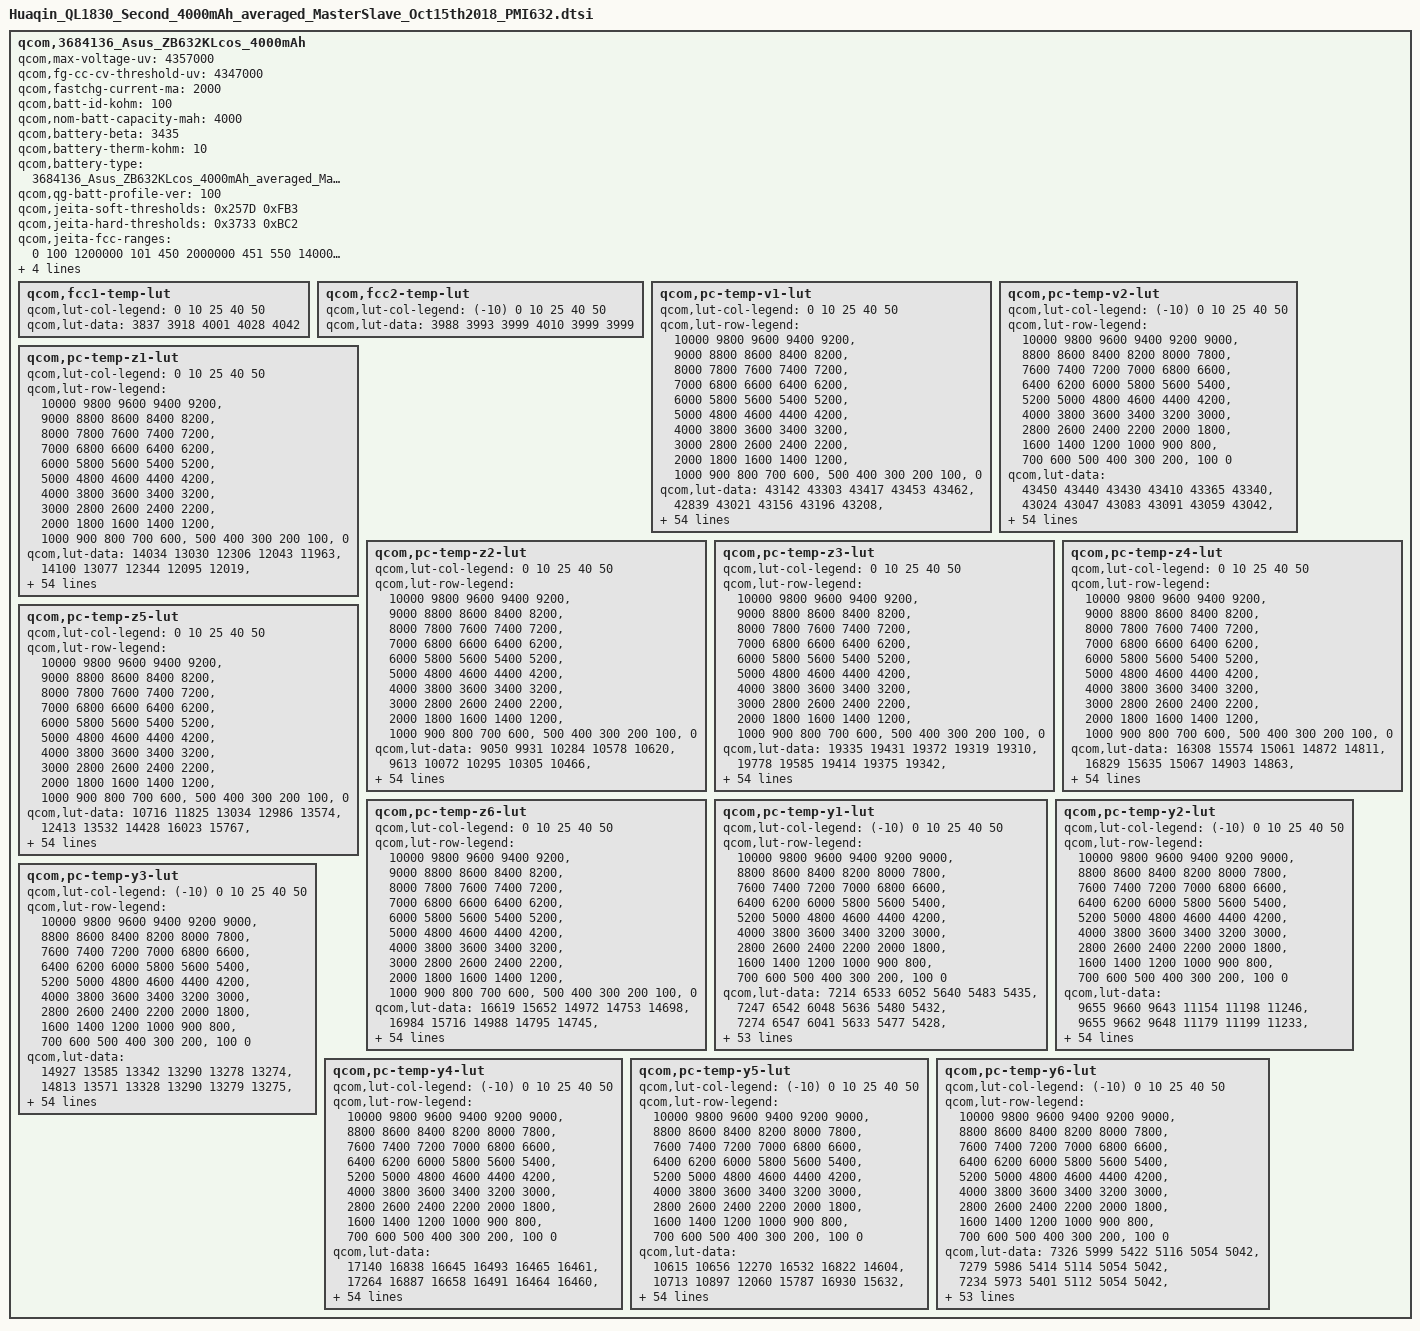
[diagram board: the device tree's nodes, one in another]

qcom,3684136_Asus_ZB632KLcos_4000mAh {
    /* 3684136_Asus_ZB632KLcos_4000mAh_averaged_MasterSlave_Oct15th2018 */
    qcom,max-voltage-uv = <4357000>;
    qcom,fg-cc-cv-threshold-uv = <4347000>;
//huaqin add by wenyaqi for jeita and FCC 2000mA at 20181016 start
    qcom,fastchg-current-ma = <2000>;
//huaqin add by wenyaqi for jeita and FCC 2000mA at 20181016 end
    qcom,batt-id-kohm = <100>;
    qcom,nom-batt-capacity-mah = <4000>;
    qcom,battery-beta = <3435>;
    qcom,battery-therm-kohm = <10>;
    qcom,battery-type = "3684136_Asus_ZB632KLcos_4000mAh_averaged_MasterSlave_Oct15th2018";
    qcom,qg-batt-profile-ver = <100>;
//huaqin add by wenyaqi for jeita and FCC 2000mA at 20181016 start
/* COOL = 15 DegC, WARM = 45 DegC */
    qcom,jeita-soft-thresholds = <0x257D 0xFB3>;
    /* COLD = 0 DegC, HOT = 55 DegC */
    qcom,jeita-hard-thresholds = <0x3733 0xBC2>;
    qcom,jeita-fcc-ranges = <0   100  1200000
                               101  450  2000000
                               451  550  1400000>;
    qcom,jeita-fv-ranges = <0   450  4357000
                            451 550  4100000>;
/*here step charge do not limit current*/
    qcom,step-chg-ranges = <3500000  4200000  2000000
                            4210000  4357000  2000000>;
//huaqin add by wenyaqi for jeita and FCC 2000mA at 20181016 end

	qcom,fcc1-temp-lut {
		qcom,lut-col-legend = <0 10 25 40 50>;
		qcom,lut-data = <3837 3918 4001 4028 4042>;
	};

	qcom,fcc2-temp-lut {
		qcom,lut-col-legend = <(-10) 0 10 25 40 50>;
		qcom,lut-data = <3988 3993 3999 4010 3999 3999>;
	};

	qcom,pc-temp-v1-lut {
		qcom,lut-col-legend = <0 10 25 40 50>;
		qcom,lut-row-legend = <10000 9800 9600 9400 9200>,
			<9000 8800 8600 8400 8200>,
			<8000 7800 7600 7400 7200>,
			<7000 6800 6600 6400 6200>,
			<6000 5800 5600 5400 5200>,
			<5000 4800 4600 4400 4200>,
			<4000 3800 3600 3400 3200>,
			<3000 2800 2600 2400 2200>,
			<2000 1800 1600 1400 1200>,
			<1000 900 800 700 600>,
			<500 400 300 200 100>,
			<0>;
		qcom,lut-data = <43142 43303 43417 43453 43462>,
			<42839 43021 43156 43196 43208>,
			<42573 42757 42884 42933 42950>,
			<42325 42505 42624 42677 42697>,
			<42092 42264 42377 42430 42454>,
			<41872 42033 42137 42189 42217>,
			<41660 41811 41904 41954 41982>,
			<41458 41595 41676 41723 41748>,
			<41259 41385 41453 41496 41519>,
			<41055 41179 41233 41270 41292>,
			<40848 40981 41021 41048 41070>,
			<40627 40789 40822 40837 40855>,
			<40361 40573 40626 40633 40646>,
			<40095 40301 40414 40435 40445>,
			<39903 40045 40181 40238 40249>,
			<39762 39881 39975 40048 40061>,
			<39636 39760 39820 39874 39883>,
			<39510 39637 39686 39709 39715>,
			<39390 39502 39544 39550 39552>,
			<39274 39366 39403 39406 39405>,
			<39161 39232 39242 39253 39253>,
			<39052 39100 39014 39051 39057>,
			<38947 38952 38763 38815 38819>,
			<38845 38747 38601 38634 38631>,
			<38748 38536 38491 38505 38500>,
			<38657 38411 38402 38396 38390>,
			<38571 38329 38324 38300 38292>,
			<38491 38271 38256 38215 38204>,
			<38415 38230 38195 38143 38128>,
			<38347 38199 38138 38079 38059>,
			<38290 38169 38089 38026 37999>,
			<38241 38141 38047 37981 37949>,
			<38203 38115 38011 37943 37905>,
			<38169 38088 37980 37909 37867>,
			<38147 38064 37955 37883 37839>,
			<38142 38038 37928 37853 37808>,
			<38141 38018 37902 37817 37767>,
			<38139 37992 37873 37776 37717>,
			<38104 37943 37827 37721 37656>,
			<38031 37862 37749 37649 37581>,
			<37945 37770 37654 37562 37492>,
			<37823 37663 37550 37458 37388>,
			<37673 37535 37426 37332 37264>,
			<37480 37374 37276 37180 37111>,
			<37217 37197 37101 37017 36953>,
			<36801 36871 36824 36808 36771>,
			<36514 36563 36587 36618 36606>,
			<36238 36276 36308 36368 36373>,
			<36011 36022 36038 36099 36114>,
			<35793 35817 35794 35836 35846>,
			<35468 35525 35462 35466 35426>,
			<34904 34989 34931 34918 34859>,
			<34214 34326 34267 34251 34176>,
			<33333 33477 33419 33400 33302>,
			<32051 32257 32181 32184 32043>,
			<30000 30000 30000 30000 30000>;
	};

	qcom,pc-temp-v2-lut {
		qcom,lut-col-legend = <(-10) 0 10 25 40 50>;
		qcom,lut-row-legend = <10000 9800 9600 9400 9200 9000>,
			<8800 8600 8400 8200 8000 7800>,
			<7600 7400 7200 7000 6800 6600>,
			<6400 6200 6000 5800 5600 5400>,
			<5200 5000 4800 4600 4400 4200>,
			<4000 3800 3600 3400 3200 3000>,
			<2800 2600 2400 2200 2000 1800>,
			<1600 1400 1200 1000 900 800>,
			<700 600 500 400 300 200>,
			<100 0>;
		qcom,lut-data = <43450 43440 43430 43410 43365 43340>,
			<43024 43047 43083 43091 43059 43042>,
			<42642 42695 42766 42795 42771 42760>,
			<42312 42390 42481 42524 42505 42497>,
			<42026 42126 42225 42276 42259 42252>,
			<41762 41876 41984 42037 42020 42013>,
			<41507 41625 41754 41803 41785 41778>,
			<41270 41384 41534 41574 41554 41548>,
			<41067 41168 41315 41346 41328 41322>,
			<40903 40975 41096 41119 41105 41099>,
			<40710 40773 40883 40902 40888 40882>,
			<40392 40536 40682 40706 40677 40670>,
			<40017 40284 40481 40516 40472 40464>,
			<39744 40042 40255 40300 40275 40267>,
			<39541 39806 39991 40054 40083 40076>,
			<39353 39589 39767 39843 39900 39893>,
			<39161 39402 39624 39693 39728 39721>,
			<38977 39230 39500 39562 39563 39555>,
			<38803 39048 39328 39413 39402 39394>,
			<38636 38857 39096 39255 39252 39243>,
			<38485 38677 38875 39077 39086 39076>,
			<38352 38512 38696 38847 38861 38855>,
			<38232 38360 38536 38610 38622 38620>,
			<38119 38232 38396 38446 38454 38453>,
			<38014 38121 38270 38322 38328 38327>,
			<37914 38029 38162 38216 38221 38219>,
			<37821 37950 38072 38122 38125 38122>,
			<37732 37885 37996 38040 38041 38037>,
			<37642 37834 37933 37966 37967 37961>,
			<37552 37794 37878 37899 37899 37891>,
			<37461 37758 37834 37845 37842 37832>,
			<37369 37725 37803 37805 37795 37782>,
			<37274 37693 37776 37772 37755 37738>,
			<37176 37656 37750 37744 37716 37692>,
			<37073 37616 37728 37722 37681 37645>,
			<36968 37570 37701 37694 37639 37591>,
			<36855 37516 37664 37650 37578 37517>,
			<36737 37449 37620 37593 37505 37432>,
			<36613 37359 37561 37529 37434 37356>,
			<36480 37226 37484 37454 37365 37289>,
			<36352 37055 37386 37367 37288 37214>,
			<36238 36819 37250 37261 37192 37120>,
			<36130 36521 37072 37132 37074 37005>,
			<36025 36165 36844 36965 36918 36852>,
			<35916 35869 36527 36753 36761 36716>,
			<35787 35664 36114 36450 36564 36547>,
			<35707 35564 35922 36220 36359 36358>,
			<35608 35457 35741 35950 36084 36094>,
			<35476 35337 35559 35694 35810 35818>,
			<35279 35165 35355 35452 35548 35538>,
			<34978 34896 35063 35094 35198 35127>,
			<34518 34447 34552 34538 34638 34541>,
			<33832 33795 33852 33818 33953 33824>,
			<32841 32858 32942 32873 33059 32894>,
			<31388 31400 31608 31525 31787 31553>,
			<27581 27778 29167 28757 29664 28951>;
	};

	qcom,pc-temp-z1-lut {
		qcom,lut-col-legend = <0 10 25 40 50>;
		qcom,lut-row-legend = <10000 9800 9600 9400 9200>,
			<9000 8800 8600 8400 8200>,
			<8000 7800 7600 7400 7200>,
			<7000 6800 6600 6400 6200>,
			<6000 5800 5600 5400 5200>,
			<5000 4800 4600 4400 4200>,
			<4000 3800 3600 3400 3200>,
			<3000 2800 2600 2400 2200>,
			<2000 1800 1600 1400 1200>,
			<1000 900 800 700 600>,
			<500 400 300 200 100>,
			<0>;
		qcom,lut-data = <14034 13030 12306 12043 11963>,
			<14100 13077 12344 12095 12019>,
			<14095 13092 12361 12099 12021>,
			<14094 13094 12364 12096 12019>,
			<14116 13096 12362 12090 12014>,
			<14142 13100 12362 12086 12009>,
			<14151 13103 12365 12082 12008>,
			<14151 13107 12368 12080 12007>,
			<14148 13117 12370 12079 12006>,
			<14145 13124 12372 12080 12007>,
			<14141 13120 12373 12081 12008>,
			<14136 13111 12370 12083 12010>,
			<14128 13107 12365 12086 12013>,
			<14120 13109 12364 12090 12017>,
			<14121 13112 12364 12092 12021>,
			<14136 13115 12366 12096 12027>,
			<14147 13123 12371 12100 12032>,
			<14138 13131 12381 12106 12037>,
			<14121 13145 12388 12111 12043>,
			<14117 13160 12396 12116 12048>,
			<14124 13166 12403 12122 12054>,
			<14134 13171 12411 12127 12059>,
			<14148 13175 12418 12133 12065>,
			<14167 13183 12421 12139 12071>,
			<14183 13192 12426 12146 12078>,
			<14210 13199 12430 12153 12084>,
			<14243 13205 12436 12158 12089>,
			<14246 13211 12443 12163 12095>,
			<14223 13221 12446 12168 12100>,
			<14206 13232 12450 12172 12105>,
			<14210 13237 12452 12176 12110>,
			<14217 13236 12454 12181 12114>,
			<14229 13237 12456 12185 12118>,
			<14274 13246 12459 12188 12122>,
			<14318 13263 12463 12190 12126>,
			<14314 13272 12467 12192 12129>,
			<14283 13277 12469 12195 12131>,
			<14265 13279 12472 12198 12133>,
			<14276 13279 12474 12200 12135>,
			<14293 13281 12476 12202 12136>,
			<14296 13285 12477 12203 12138>,
			<14283 13296 12479 12205 12139>,
			<14271 13302 12481 12207 12141>,
			<14262 13301 12485 12209 12142>,
			<14245 13305 12494 12215 12145>,
			<14238 13295 12505 12222 12153>,
			<14235 13313 12511 12237 12165>,
			<14233 13295 12527 12260 12188>,
			<14239 13299 12532 12284 12216>,
			<14243 13321 12551 12308 12245>,
			<14275 13337 12571 12319 12268>,
			<14273 13347 12580 12334 12280>,
			<14293 13370 12609 12350 12297>,
			<14320 13412 12635 12376 12321>,
			<14320 13412 12635 12376 12321>,
			<14320 13412 12635 12376 12321>;
	};

	qcom,pc-temp-z2-lut {
		qcom,lut-col-legend = <0 10 25 40 50>;
		qcom,lut-row-legend = <10000 9800 9600 9400 9200>,
			<9000 8800 8600 8400 8200>,
			<8000 7800 7600 7400 7200>,
			<7000 6800 6600 6400 6200>,
			<6000 5800 5600 5400 5200>,
			<5000 4800 4600 4400 4200>,
			<4000 3800 3600 3400 3200>,
			<3000 2800 2600 2400 2200>,
			<2000 1800 1600 1400 1200>,
			<1000 900 800 700 600>,
			<500 400 300 200 100>,
			<0>;
		qcom,lut-data = <9050 9931 10284 10578 10620>,
			<9613 10072 10295 10305 10466>,
			<9837 10099 10349 10447 10469>,
			<9941 10080 10360 10517 10469>,
			<9968 10057 10336 10499 10435>,
			<9984 10035 10308 10476 10389>,
			<9988 10012 10285 10468 10381>,
			<9986 9997 10266 10462 10390>,
			<9983 9985 10265 10459 10400>,
			<9970 9979 10279 10457 10406>,
			<9936 9978 10297 10456 10411>,
			<9907 9978 10318 10447 10416>,
			<9890 9979 10339 10423 10428>,
			<9878 9992 10346 10411 10440>,
			<9874 10012 10347 10405 10450>,
			<9873 10035 10347 10401 10459>,
			<9875 10063 10350 10402 10461>,
			<9880 10085 10358 10406 10460>,
			<9889 10101 10366 10407 10460>,
			<9892 10114 10376 10406 10462>,
			<9885 10130 10382 10406 10466>,
			<9875 10148 10364 10445 10542>,
			<9869 10156 10331 10536 10776>,
			<9865 10146 10324 10566 10873>,
			<9863 10132 10340 10547 10713>,
			<9870 10132 10352 10514 10506>,
			<9885 10150 10351 10468 10413>,
			<9899 10167 10349 10406 10351>,
			<9915 10177 10342 10373 10316>,
			<9932 10184 10314 10355 10295>,
			<9948 10191 10295 10347 10282>,
			<9964 10197 10300 10351 10281>,
			<9980 10203 10313 10365 10286>,
			<9998 10214 10330 10382 10299>,
			<10012 10228 10356 10415 10344>,
			<9912 10241 10378 10441 10394>,
			<9530 10252 10391 10446 10424>,
			<9301 10263 10402 10448 10447>,
			<9328 10279 10415 10450 10456>,
			<9372 10298 10431 10461 10458>,
			<9388 10304 10443 10469 10460>,
			<9389 10301 10447 10474 10478>,
			<9386 10297 10448 10478 10500>,
			<9380 10291 10436 10462 10488>,
			<9334 10130 10419 10438 10459>,
			<9233 9817 10342 10365 10412>,
			<9176 10144 10219 10274 10327>,
			<9157 9992 10081 10151 10231>,
			<9143 9821 10045 10159 10232>,
			<9131 9446 10132 10253 10342>,
			<9122 9214 10040 10305 10315>,
			<9169 9180 9915 10288 10269>,
			<9186 9150 9856 10249 10260>,
			<9150 9123 9674 10187 10221>,
			<9150 9123 9674 10187 10221>,
			<9150 9123 9674 10187 10221>;
	};

	qcom,pc-temp-z3-lut {
		qcom,lut-col-legend = <0 10 25 40 50>;
		qcom,lut-row-legend = <10000 9800 9600 9400 9200>,
			<9000 8800 8600 8400 8200>,
			<8000 7800 7600 7400 7200>,
			<7000 6800 6600 6400 6200>,
			<6000 5800 5600 5400 5200>,
			<5000 4800 4600 4400 4200>,
			<4000 3800 3600 3400 3200>,
			<3000 2800 2600 2400 2200>,
			<2000 1800 1600 1400 1200>,
			<1000 900 800 700 600>,
			<500 400 300 200 100>,
			<0>;
		qcom,lut-data = <19335 19431 19372 19319 19310>,
			<19778 19585 19414 19375 19342>,
			<19863 19652 19466 19390 19362>,
			<19891 19686 19486 19397 19374>,
			<19881 19702 19491 19403 19374>,
			<19859 19705 19493 19407 19374>,
			<19846 19706 19491 19404 19373>,
			<19840 19706 19488 19396 19370>,
			<19837 19706 19485 19391 19367>,
			<19844 19705 19482 19389 19366>,
			<19870 19696 19478 19388 19365>,
			<19890 19673 19470 19383 19363>,
			<19898 19664 19460 19375 19358>,
			<19903 19664 19457 19372 19354>,
			<19898 19664 19456 19372 19353>,
			<19866 19652 19456 19372 19353>,
			<19830 19616 19450 19371 19352>,
			<19800 19598 19440 19369 19350>,
			<19773 19597 19438 19368 19348>,
			<19765 19598 19438 19368 19346>,
			<19787 19601 19440 19368 19345>,
			<19820 19606 19452 19371 19351>,
			<19846 19612 19467 19381 19372>,
			<19874 19622 19469 19389 19384>,
			<19886 19633 19460 19396 19388>,
			<19883 19635 19454 19402 19390>,
			<19875 19634 19463 19411 19391>,
			<19868 19633 19479 19421 19392>,
			<19859 19630 19484 19423 19391>,
			<19849 19626 19486 19418 19388>,
			<19839 19622 19486 19412 19384>,
			<19829 19617 19482 19406 19380>,
			<19817 19612 19474 19400 19376>,
			<19805 19608 19468 19394 19371>,
			<19789 19604 19463 19389 19363>,
			<19701 19599 19459 19384 19357>,
			<19445 19592 19454 19381 19353>,
			<19289 19586 19449 19378 19351>,
			<19281 19583 19446 19374 19350>,
			<19276 19580 19444 19369 19350>,
			<19275 19578 19443 19365 19350>,
			<19274 19575 19441 19363 19345>,
			<19274 19572 19439 19362 19339>,
			<19274 19564 19435 19362 19341>,
			<19277 19362 19429 19363 19343>,
			<19290 19296 19437 19369 19346>,
			<19307 19570 19447 19373 19355>,
			<19314 19597 19461 19381 19363>,
			<19318 19615 19454 19378 19360>,
			<19324 19495 19450 19372 19350>,
			<19352 19328 19407 19366 19358>,
			<19518 19332 19341 19371 19361>,
			<19684 19333 19340 19371 19362>,
			<19733 19344 19273 19376 19363>,
			<19733 19344 19273 19376 19363>,
			<19733 19344 19273 19376 19363>;
	};

	qcom,pc-temp-z4-lut {
		qcom,lut-col-legend = <0 10 25 40 50>;
		qcom,lut-row-legend = <10000 9800 9600 9400 9200>,
			<9000 8800 8600 8400 8200>,
			<8000 7800 7600 7400 7200>,
			<7000 6800 6600 6400 6200>,
			<6000 5800 5600 5400 5200>,
			<5000 4800 4600 4400 4200>,
			<4000 3800 3600 3400 3200>,
			<3000 2800 2600 2400 2200>,
			<2000 1800 1600 1400 1200>,
			<1000 900 800 700 600>,
			<500 400 300 200 100>,
			<0>;
		qcom,lut-data = <16308 15574 15061 14872 14811>,
			<16829 15635 15067 14903 14863>,
			<16688 15614 15028 14883 14848>,
			<16501 15444 14981 14859 14828>,
			<16310 15259 14919 14830 14807>,
			<16098 15152 14865 14800 14786>,
			<15926 15064 14826 14779 14769>,
			<15794 14998 14795 14763 14755>,
			<15676 14948 14778 14751 14743>,
			<15555 14907 14767 14742 14735>,
			<15433 14868 14757 14736 14729>,
			<15350 14833 14744 14730 14723>,
			<15309 14817 14733 14725 14718>,
			<15278 14812 14729 14719 14712>,
			<15243 14807 14728 14712 14705>,
			<15204 14800 14726 14704 14698>,
			<15173 14791 14717 14697 14691>,
			<15156 14781 14703 14690 14685>,
			<15145 14768 14697 14686 14681>,
			<15124 14757 14694 14683 14678>,
			<15066 14754 14693 14681 14677>,
			<14996 14752 14753 14714 14697>,
			<14942 14752 14856 14797 14762>,
			<14893 14826 14885 14826 14790>,
			<14866 14934 14886 14813 14779>,
			<14859 14955 14882 14794 14762>,
			<14855 14951 14857 14772 14745>,
			<14855 14944 14816 14746 14728>,
			<14858 14924 14791 14732 14717>,
			<14861 14889 14774 14726 14710>,
			<14861 14861 14763 14722 14705>,
			<14859 14837 14758 14717 14701>,
			<14856 14818 14754 14713 14697>,
			<14846 14804 14751 14709 14695>,
			<14836 14792 14748 14706 14692>,
			<14901 14783 14746 14703 14691>,
			<15148 14775 14745 14705 14693>,
			<15296 14769 14744 14709 14697>,
			<15286 14772 14746 14713 14698>,
			<15266 14781 14753 14718 14697>,
			<15254 14785 14757 14721 14694>,
			<15247 14777 14752 14718 14693>,
			<15237 14765 14744 14713 14693>,
			<15218 14752 14741 14716 14695>,
			<15141 14900 14720 14710 14694>,
			<15185 14984 14711 14700 14689>,
			<15261 14766 14727 14712 14692>,
			<15337 14791 14721 14706 14692>,
			<15384 14798 14713 14691 14685>,
			<15411 14931 14705 14683 14676>,
			<15423 15120 14743 14686 14668>,
			<15318 15127 14815 14681 14664>,
			<15208 15137 14819 14682 14663>,
			<15238 15156 14901 14682 14665>,
			<15238 15156 14901 14682 14665>,
			<15238 15156 14901 14682 14665>;
	};

	qcom,pc-temp-z5-lut {
		qcom,lut-col-legend = <0 10 25 40 50>;
		qcom,lut-row-legend = <10000 9800 9600 9400 9200>,
			<9000 8800 8600 8400 8200>,
			<8000 7800 7600 7400 7200>,
			<7000 6800 6600 6400 6200>,
			<6000 5800 5600 5400 5200>,
			<5000 4800 4600 4400 4200>,
			<4000 3800 3600 3400 3200>,
			<3000 2800 2600 2400 2200>,
			<2000 1800 1600 1400 1200>,
			<1000 900 800 700 600>,
			<500 400 300 200 100>,
			<0>;
		qcom,lut-data = <10716 11825 13034 12986 13574>,
			<12413 13532 14428 16023 15767>,
			<12971 14567 16441 17152 17374>,
			<13306 15223 17652 17947 18319>,
			<13573 15752 18274 18765 18358>,
			<13774 16212 18767 19299 18319>,
			<13972 16625 19256 19335 18428>,
			<14170 17213 19779 19302 18784>,
			<14385 18262 20474 19301 19199>,
			<14677 19020 21485 19712 19695>,
			<15060 19033 22090 20171 20139>,
			<15410 18987 22032 20007 20150>,
			<15760 19084 21855 19401 19898>,
			<16045 21110 21937 19174 19758>,
			<16028 23238 22601 19821 20268>,
			<15567 22663 23109 20826 21199>,
			<15011 20343 23218 21709 22033>,
			<14547 19252 23290 22638 22915>,
			<14111 20120 23617 23563 23655>,
			<14003 21792 25211 24680 24301>,
			<14640 23846 27324 25433 24761>,
			<15826 26872 31191 25106 24825>,
			<17574 30336 35420 23935 24624>,
			<20531 35277 34699 22541 24194>,
			<23380 39915 26613 20331 21992>,
			<25699 40228 21071 18720 19776>,
			<27792 37142 21379 19851 20118>,
			<29548 34063 22287 22833 21786>,
			<31285 32270 23598 24608 23279>,
			<32326 30894 25950 25622 24427>,
			<32445 30495 27785 26260 25498>,
			<32498 30395 28610 26604 26664>,
			<32482 30351 29190 26975 27799>,
			<31657 31003 29499 27000 28039>,
			<29977 32511 29709 26872 26968>,
			<25820 33232 29796 26658 25464>,
			<16368 33413 29090 25871 24095>,
			<11022 33551 27657 24301 22672>,
			<11010 33807 26534 22641 21616>,
			<11009 34169 25465 20580 20924>,
			<11014 34284 24792 19080 20168>,
			<11031 33646 24478 18598 18715>,
			<11033 32514 24090 18262 17329>,
			<11006 30261 22651 17721 16948>,
			<11080 16733 23055 18064 17036>,
			<11127 12669 25812 20230 18243>,
			<11192 24806 23285 19937 19813>,
			<11114 21578 23121 20891 21563>,
			<10902 20386 23336 22294 23427>,
			<10757 13136 25399 22645 21239>,
			<10769 10920 16743 18950 21715>,
			<11389 10897 13850 19477 22305>,
			<11864 10835 13687 19195 22130>,
			<11728 10779 11246 19336 21556>,
			<11728 10779 11246 19336 21556>,
			<11728 10779 11246 19336 21556>;
	};

	qcom,pc-temp-z6-lut {
		qcom,lut-col-legend = <0 10 25 40 50>;
		qcom,lut-row-legend = <10000 9800 9600 9400 9200>,
			<9000 8800 8600 8400 8200>,
			<8000 7800 7600 7400 7200>,
			<7000 6800 6600 6400 6200>,
			<6000 5800 5600 5400 5200>,
			<5000 4800 4600 4400 4200>,
			<4000 3800 3600 3400 3200>,
			<3000 2800 2600 2400 2200>,
			<2000 1800 1600 1400 1200>,
			<1000 900 800 700 600>,
			<500 400 300 200 100>,
			<0>;
		qcom,lut-data = <16619 15652 14972 14753 14698>,
			<16984 15716 14988 14795 14745>,
			<16900 15713 14990 14795 14748>,
			<16786 15628 14986 14792 14747>,
			<16663 15532 14956 14783 14740>,
			<16522 15470 14924 14769 14729>,
			<16410 15416 14902 14757 14720>,
			<16325 15375 14884 14744 14712>,
			<16253 15345 14873 14736 14706>,
			<16189 15317 14867 14732 14702>,
			<16132 15283 14861 14728 14698>,
			<16087 15249 14849 14723 14694>,
			<16058 15232 14837 14717 14690>,
			<16033 15227 14833 14712 14686>,
			<16002 15224 14832 14710 14683>,
			<15962 15213 14831 14708 14680>,
			<15927 15194 14825 14705 14678>,
			<15903 15184 14817 14702 14675>,
			<15883 15183 14815 14700 14673>,
			<15868 15181 14816 14700 14672>,
			<15855 15182 14818 14700 14672>,
			<15846 15187 14851 14717 14685>,
			<15844 15195 14905 14761 14726>,
			<15844 15236 14920 14776 14745>,
			<15845 15290 14919 14775 14742>,
			<15845 15301 14917 14774 14739>,
			<15844 15302 14912 14772 14735>,
			<15844 15302 14905 14766 14729>,
			<15844 15295 14900 14762 14724>,
			<15843 15280 14895 14757 14720>,
			<15842 15268 14891 14753 14716>,
			<15839 15257 14887 14749 14713>,
			<15835 15248 14882 14744 14710>,
			<15828 15242 14879 14740 14706>,
			<15819 15237 14876 14736 14701>,
			<15805 15233 14874 14733 14697>,
			<15785 15229 14873 14733 14697>,
			<15771 15227 14871 14733 14698>,
			<15766 15229 14872 14733 14698>,
			<15764 15236 14875 14733 14697>,
			<15762 15239 14877 14733 14697>,
			<15760 15237 14875 14732 14694>,
			<15759 15235 14872 14729 14691>,
			<15754 15232 14871 14732 14694>,
			<15735 15213 14865 14731 14695>,
			<15770 15230 14876 14733 14697>,
			<15813 15284 14901 14747 14707>,
			<15855 15323 14927 14760 14718>,
			<15887 15353 14943 14765 14722>,
			<15912 15368 14956 14767 14719>,
			<15951 15390 14965 14772 14725>,
			<16002 15423 14978 14778 14730>,
			<16059 15457 14996 14787 14735>,
			<16129 15508 15022 14800 14744>,
			<16129 15508 15022 14800 14744>,
			<16129 15508 15022 14800 14744>;
	};

	qcom,pc-temp-y1-lut {
		qcom,lut-col-legend = <(-10) 0 10 25 40 50>;
		qcom,lut-row-legend = <10000 9800 9600 9400 9200 9000>,
			<8800 8600 8400 8200 8000 7800>,
			<7600 7400 7200 7000 6800 6600>,
			<6400 6200 6000 5800 5600 5400>,
			<5200 5000 4800 4600 4400 4200>,
			<4000 3800 3600 3400 3200 3000>,
			<2800 2600 2400 2200 2000 1800>,
			<1600 1400 1200 1000 900 800>,
			<700 600 500 400 300 200>,
			<100 0>;
		qcom,lut-data = <7214 6533 6052 5640 5483 5435>,
			<7247 6542 6048 5636 5480 5432>,
			<7274 6547 6041 5633 5477 5428>,
			<7293 6550 6033 5631 5474 5423>,
			<7305 6551 6027 5629 5472 5419>,
			<7309 6551 6024 5629 5470 5417>,
			<7297 6550 6025 5629 5468 5416>,
			<7278 6547 6025 5631 5466 5416>,
			<7276 6547 6026 5631 5465 5415>,
			<7288 6550 6030 5630 5463 5415>,
			<7297 6553 6033 5630 5462 5414>,
			<7302 6556 6032 5630 5462 5414>,
			<7313 6559 6032 5630 5461 5413>,
			<7322 6564 6035 5632 5462 5414>,
			<7332 6576 6044 5636 5465 5416>,
			<7337 6584 6052 5639 5467 5418>,
			<7332 6588 6055 5639 5470 5420>,
			<7324 6592 6057 5640 5472 5422>,
			<7322 6598 6058 5641 5474 5425>,
			<7318 6604 6058 5642 5476 5428>,
			<7315 6608 6058 5645 5479 5432>,
			<7317 6607 6059 5647 5482 5436>,
			<7319 6604 6063 5650 5486 5440>,
			<7325 6605 6066 5654 5490 5444>,
			<7342 6609 6070 5659 5495 5449>,
			<7358 6614 6074 5663 5500 5453>,
			<7363 6623 6079 5666 5504 5458>,
			<7367 6635 6085 5669 5508 5462>,
			<7372 6641 6087 5671 5511 5466>,
			<7388 6652 6088 5675 5514 5470>,
			<7397 6661 6089 5678 5517 5473>,
			<7386 6654 6091 5682 5521 5476>,
			<7367 6642 6092 5686 5525 5479>,
			<7365 6640 6094 5687 5528 5482>,
			<7386 6644 6096 5687 5530 5485>,
			<7407 6649 6098 5687 5532 5487>,
			<7421 6659 6102 5688 5533 5489>,
			<7436 6672 6106 5690 5535 5490>,
			<7439 6676 6109 5691 5536 5491>,
			<7424 6672 6113 5692 5536 5492>,
			<7410 6670 6116 5694 5537 5493>,
			<7402 6680 6117 5697 5540 5495>,
			<7397 6696 6119 5700 5545 5498>,
			<7413 6702 6135 5704 5548 5500>,
			<7415 6711 6143 5713 5555 5506>,
			<7412 6718 6143 5721 5568 5519>,
			<7472 6737 6147 5724 5577 5531>,
			<7425 6726 6163 5727 5587 5543>,
			<7474 6744 6166 5732 5591 5555>,
			<7522 6751 6162 5740 5595 5558>,
			<7489 6759 6173 5740 5599 5562>,
			<7559 6761 6191 5751 5606 5568>,
			<7640 6789 6219 5762 5616 5580>,
			<7743 6875 6241 5782 5627 5593>,
			<7743 6875 6241 5782 5627 5593>,
			<7743 6875 6241 5782 5627 5593>;
	};

	qcom,pc-temp-y2-lut {
		qcom,lut-col-legend = <(-10) 0 10 25 40 50>;
		qcom,lut-row-legend = <10000 9800 9600 9400 9200 9000>,
			<8800 8600 8400 8200 8000 7800>,
			<7600 7400 7200 7000 6800 6600>,
			<6400 6200 6000 5800 5600 5400>,
			<5200 5000 4800 4600 4400 4200>,
			<4000 3800 3600 3400 3200 3000>,
			<2800 2600 2400 2200 2000 1800>,
			<1600 1400 1200 1000 900 800>,
			<700 600 500 400 300 200>,
			<100 0>;
		qcom,lut-data = <9655 9660 9643 11154 11198 11246>,
			<9655 9662 9648 11179 11199 11233>,
			<9655 9665 9864 11183 11195 11217>,
			<9656 9667 10039 11171 11186 11200>,
			<9656 9670 10171 11147 11175 11181>,
			<9656 9672 10264 11115 11162 11161>,
			<9656 9675 10307 11057 11142 11136>,
			<9656 9677 10312 10996 11122 11111>,
			<9656 9680 10345 10983 11110 11102>,
			<9657 9684 10527 10982 11103 11101>,
			<9657 9687 10655 10980 11095 11098>,
			<9657 9693 10674 10965 11071 11080>,
			<9657 9698 10698 10944 11038 11056>,
			<9657 9699 10724 10941 11013 11048>,
			<9658 9697 10753 10944 10990 11055>,
			<9658 9696 10781 10948 10980 11059>,
			<9658 9698 10810 10956 10987 11042>,
			<9658 9701 10834 10971 11003 11022>,
			<9658 9701 10837 11000 11032 11021>,
			<9658 9697 10834 11063 11113 11042>,
			<9658 9693 10832 11099 11162 11066>,
			<9658 9691 10855 11102 11154 11109>,
			<9658 9689 10892 11104 11140 11163>,
			<9658 9689 10858 11112 11140 11185>,
			<9658 9689 10621 11138 11150 11198>,
			<9658 9689 10465 11155 11161 11208>,
			<9658 9688 10625 11163 11186 11220>,
			<9658 9687 10872 11169 11220 11233>,
			<9658 9686 10917 11174 11239 11250>,
			<9658 9685 10907 11183 11250 11273>,
			<9658 9685 10896 11189 11256 11286>,
			<9657 9684 10883 11190 11257 11283>,
			<9657 9682 10866 11189 11255 11277>,
			<9657 9681 10849 11181 11249 11270>,
			<9657 9679 10828 11158 11216 11259>,
			<9657 9677 10811 11143 11194 11244>,
			<9656 9674 10776 11136 11184 11218>,
			<9656 9672 10733 11127 11167 11187>,
			<9656 9670 10722 11112 11158 11170>,
			<9656 9668 10721 11085 11148 11156>,
			<9656 9666 10712 11066 11142 11144>,
			<9655 9665 10674 11050 11148 11123>,
			<9655 9663 10585 11025 11155 11103>,
			<9655 9661 10037 10957 11083 11118>,
			<9654 9660 9761 10878 11036 11096>,
			<9654 9659 9700 10718 10973 10989>,
			<9654 9658 9691 10764 10905 10913>,
			<9654 9657 9687 10820 10899 10937>,
			<9654 9657 9684 10830 10942 10995>,
			<9653 9656 9679 10865 10996 11005>,
			<9652 9655 9676 10151 10978 11025>,
			<9651 9654 9672 10110 10968 10971>,
			<9650 9653 9667 10200 10886 10922>,
			<9649 9651 9661 10044 10784 10807>,
			<9649 9651 9661 10044 10784 10807>,
			<9649 9651 9661 10044 10784 10807>;
	};

	qcom,pc-temp-y3-lut {
		qcom,lut-col-legend = <(-10) 0 10 25 40 50>;
		qcom,lut-row-legend = <10000 9800 9600 9400 9200 9000>,
			<8800 8600 8400 8200 8000 7800>,
			<7600 7400 7200 7000 6800 6600>,
			<6400 6200 6000 5800 5600 5400>,
			<5200 5000 4800 4600 4400 4200>,
			<4000 3800 3600 3400 3200 3000>,
			<2800 2600 2400 2200 2000 1800>,
			<1600 1400 1200 1000 900 800>,
			<700 600 500 400 300 200>,
			<100 0>;
		qcom,lut-data = <14927 13585 13342 13290 13278 13274>,
			<14813 13571 13328 13290 13279 13275>,
			<14705 13557 13320 13291 13280 13276>,
			<14603 13544 13315 13291 13281 13276>,
			<14508 13533 13314 13291 13282 13277>,
			<14423 13523 13314 13291 13282 13277>,
			<14336 13514 13321 13292 13282 13278>,
			<14262 13506 13334 13294 13281 13278>,
			<14235 13501 13340 13295 13281 13278>,
			<14226 13496 13350 13297 13282 13278>,
			<14214 13494 13358 13300 13283 13279>,
			<14163 13494 13363 13304 13282 13279>,
			<14089 13494 13367 13308 13282 13279>,
			<14051 13491 13367 13310 13283 13279>,
			<14031 13480 13361 13310 13286 13279>,
			<14017 13472 13357 13310 13288 13279>,
			<14007 13470 13357 13311 13288 13281>,
			<14000 13469 13358 13312 13289 13283>,
			<13993 13466 13357 13313 13290 13285>,
			<13984 13457 13348 13313 13293 13286>,
			<13979 13448 13341 13313 13295 13287>,
			<13980 13439 13338 13308 13291 13284>,
			<13984 13431 13335 13301 13284 13279>,
			<13990 13431 13331 13298 13282 13278>,
			<14002 13437 13321 13297 13282 13277>,
			<14016 13446 13315 13297 13281 13277>,
			<14033 13457 13323 13297 13281 13277>,
			<14053 13470 13334 13298 13281 13278>,
			<14072 13483 13338 13298 13281 13278>,
			<14091 13496 13339 13297 13281 13278>,
			<14111 13508 13341 13297 13281 13277>,
			<14131 13520 13342 13298 13282 13278>,
			<14152 13532 13344 13300 13284 13278>,
			<14176 13542 13346 13302 13285 13278>,
			<14202 13552 13348 13303 13285 13278>,
			<14230 13562 13350 13304 13286 13278>,
			<14258 13576 13353 13304 13285 13278>,
			<14289 13592 13355 13305 13284 13278>,
			<14324 13610 13358 13305 13284 13278>,
			<14364 13631 13361 13306 13285 13279>,
			<14412 13656 13364 13308 13285 13279>,
			<14476 13694 13366 13311 13287 13281>,
			<14558 13729 13368 13314 13290 13283>,
			<14664 13742 13384 13318 13290 13283>,
			<14803 13780 13407 13318 13292 13286>,
			<14848 13850 13401 13315 13295 13286>,
			<14926 13911 13387 13315 13293 13286>,
			<15095 13996 13391 13311 13289 13286>,
			<15321 14104 13402 13307 13288 13286>,
			<15672 14260 13412 13310 13290 13286>,
			<16373 14480 13448 13295 13290 13283>,
			<18128 14856 13490 13297 13285 13283>,
			<21615 15633 13580 13301 13292 13285>,
			<28202 17430 13803 13315 13294 13289>,
			<28202 17430 13803 13315 13294 13289>,
			<28202 17430 13803 13315 13294 13289>;
	};

	qcom,pc-temp-y4-lut {
		qcom,lut-col-legend = <(-10) 0 10 25 40 50>;
		qcom,lut-row-legend = <10000 9800 9600 9400 9200 9000>,
			<8800 8600 8400 8200 8000 7800>,
			<7600 7400 7200 7000 6800 6600>,
			<6400 6200 6000 5800 5600 5400>,
			<5200 5000 4800 4600 4400 4200>,
			<4000 3800 3600 3400 3200 3000>,
			<2800 2600 2400 2200 2000 1800>,
			<1600 1400 1200 1000 900 800>,
			<700 600 500 400 300 200>,
			<100 0>;
		qcom,lut-data = <17140 16838 16645 16493 16465 16461>,
			<17264 16887 16658 16491 16464 16460>,
			<17382 16940 16666 16491 16463 16460>,
			<17493 16990 16671 16494 16462 16460>,
			<17592 17032 16675 16496 16463 16460>,
			<17678 17061 16678 16498 16463 16460>,
			<17762 17076 16682 16501 16466 16461>,
			<17830 17089 16687 16505 16470 16463>,
			<17852 17124 16686 16508 16473 16465>,
			<17861 17220 16679 16512 16476 16467>,
			<17864 17279 16679 16517 16479 16469>,
			<17726 17248 16718 16528 16485 16472>,
			<17499 17189 16773 16542 16493 16477>,
			<17448 17151 16789 16550 16499 16482>,
			<17447 17122 16792 16556 16503 16487>,
			<17446 17104 16797 16564 16508 16493>,
			<17436 17097 16847 16585 16517 16500>,
			<17417 17092 16919 16619 16532 16508>,
			<17401 17077 16913 16659 16555 16524>,
			<17384 17035 16805 16713 16599 16556>,
			<17373 16997 16708 16739 16623 16575>,
			<17368 16977 16658 16656 16578 16542>,
			<17364 16964 16625 16536 16502 16488>,
			<17359 16963 16622 16504 16477 16469>,
			<17353 16974 16637 16494 16467 16461>,
			<17346 16991 16648 16490 16463 16458>,
			<17341 17016 16644 16493 16465 16458>,
			<17337 17053 16640 16498 16468 16458>,
			<17330 17096 16649 16505 16471 16460>,
			<17318 17150 16680 16514 16477 16464>,
			<17304 17208 16717 16524 16483 16470>,
			<17288 17265 16759 16537 16491 16478>,
			<17270 17324 16807 16552 16500 16485>,
			<17250 17384 16856 16570 16506 16487>,
			<17230 17446 16909 16591 16512 16488>,
			<17208 17504 16963 16603 16515 16488>,
			<17182 17565 17014 16607 16509 16483>,
			<17155 17618 17065 16609 16499 16474>,
			<17129 17625 17120 16616 16499 16473>,
			<17101 17596 17182 16630 16507 16481>,
			<17086 17544 17226 16650 16518 16489>,
			<17090 17387 17249 16687 16529 16495>,
			<17102 17154 17259 16736 16544 16502>,
			<17137 16961 17228 16805 16565 16510>,
			<17185 16879 17091 16811 16602 16535>,
			<17154 16840 16770 16676 16583 16533>,
			<17154 16854 16747 16632 16551 16516>,
			<17181 16891 16742 16591 16529 16505>,
			<17213 16961 16756 16581 16520 16501>,
			<17236 17006 16803 16591 16518 16498>,
			<17283 17070 16812 16603 16502 16480>,
			<17632 17051 16752 16576 16489 16478>,
			<18638 17107 16766 16581 16500 16485>,
			<22121 17760 16876 16626 16520 16515>,
			<22121 17760 16876 16626 16520 16515>,
			<22121 17760 16876 16626 16520 16515>;
	};

	qcom,pc-temp-y5-lut {
		qcom,lut-col-legend = <(-10) 0 10 25 40 50>;
		qcom,lut-row-legend = <10000 9800 9600 9400 9200 9000>,
			<8800 8600 8400 8200 8000 7800>,
			<7600 7400 7200 7000 6800 6600>,
			<6400 6200 6000 5800 5600 5400>,
			<5200 5000 4800 4600 4400 4200>,
			<4000 3800 3600 3400 3200 3000>,
			<2800 2600 2400 2200 2000 1800>,
			<1600 1400 1200 1000 900 800>,
			<700 600 500 400 300 200>,
			<100 0>;
		qcom,lut-data = <10615 10656 12270 16532 16822 14604>,
			<10713 10897 12060 15787 16930 15632>,
			<10843 11129 11921 15256 16949 16270>,
			<10980 11326 11838 14881 16900 16610>,
			<11097 11464 11796 14601 16800 16747>,
			<11170 11516 11778 14355 16666 16772>,
			<11201 11465 12387 14220 16146 16531>,
			<11229 11384 13341 14250 15398 16080>,
			<11532 11387 13599 14316 15085 15782>,
			<12961 11526 13986 14354 14891 15580>,
			<13918 11749 14240 14414 14693 15355>,
			<13211 12427 14280 14716 14278 15002>,
			<12047 13290 14339 15078 13809 14603>,
			<11818 13394 14329 15062 13803 14311>,
			<11955 13049 14220 14693 14217 14053>,
			<12111 12820 14150 14348 14486 13935>,
			<12252 13042 14818 14130 14279 14066>,
			<12378 13400 15918 13975 13956 14307>,
			<12409 13431 16304 14178 13969 14457>,
			<12406 13159 16468 15258 14439 14585>,
			<12407 12857 16544 16270 15035 14788>,
			<12532 12556 16513 16978 15757 15608>,
			<12804 12263 16439 17506 16497 16777>,
			<13071 12231 16147 17621 16818 17345>,
			<13359 12415 14826 17652 16999 17712>,
			<13653 12680 13973 17664 17072 17899>,
			<13958 13027 14923 17605 16767 17880>,
			<14248 13484 16392 17469 16216 17759>,
			<14431 13965 16641 17172 15869 17486>,
			<14569 14515 16446 16509 15554 16754>,
			<14635 14999 16303 16204 15399 16201>,
			<14600 15373 16188 16415 15694 15961>,
			<14503 15677 16018 16690 16200 15757>,
			<14368 15852 15936 16794 16428 15738>,
			<14122 15954 15861 16868 16571 15826>,
			<13832 16061 15803 16896 16607 15881>,
			<13518 16212 15765 16820 16387 15736>,
			<13125 16393 15737 16678 16028 15487>,
			<12665 16632 15736 16542 15750 15340>,
			<12053 17002 15760 16394 15429 15114>,
			<11557 17223 15798 16295 15262 14984>,
			<11313 17176 15877 16235 15654 15452>,
			<11156 17007 16023 16194 16054 15931>,
			<11063 13808 16451 16195 15630 15824>,
			<11061 11965 16701 16368 15725 16150>,
			<11113 11659 13948 16644 16650 15515>,
			<11218 11527 12406 16776 16176 15227>,
			<11319 11540 12032 16305 14954 15636>,
			<11401 11595 11914 15061 15044 15971>,
			<11367 11740 11722 15393 15375 16170>,
			<11113 11612 12051 12782 16566 16302>,
			<10314 11486 11952 13168 15341 16479>,
			<9590 11070 11814 13481 17860 16755>,
			<9151 10011 11709 13749 17197 18314>,
			<9151 10011 11709 13749 17197 18314>,
			<9151 10011 11709 13749 17197 18314>;
	};

	qcom,pc-temp-y6-lut {
		qcom,lut-col-legend = <(-10) 0 10 25 40 50>;
		qcom,lut-row-legend = <10000 9800 9600 9400 9200 9000>,
			<8800 8600 8400 8200 8000 7800>,
			<7600 7400 7200 7000 6800 6600>,
			<6400 6200 6000 5800 5600 5400>,
			<5200 5000 4800 4600 4400 4200>,
			<4000 3800 3600 3400 3200 3000>,
			<2800 2600 2400 2200 2000 1800>,
			<1600 1400 1200 1000 900 800>,
			<700 600 500 400 300 200>,
			<100 0>;
		qcom,lut-data = <7326 5999 5422 5116 5054 5042>,
			<7279 5986 5414 5114 5054 5042>,
			<7234 5973 5401 5112 5054 5042>,
			<7191 5960 5388 5110 5054 5042>,
			<7150 5947 5376 5110 5054 5042>,
			<7111 5934 5371 5109 5054 5042>,
			<7070 5918 5369 5110 5055 5043>,
			<7034 5904 5368 5111 5055 5043>,
			<7016 5903 5368 5112 5056 5044>,
			<7008 5913 5367 5114 5057 5045>,
			<6996 5919 5368 5116 5058 5046>,
			<6920 5907 5377 5122 5060 5047>,
			<6806 5885 5390 5128 5062 5048>,
			<6762 5867 5391 5132 5064 5050>,
			<6746 5851 5385 5134 5067 5052>,
			<6734 5840 5381 5137 5070 5054>,
			<6724 5837 5395 5144 5074 5057>,
			<6715 5834 5416 5154 5079 5061>,
			<6705 5827 5414 5166 5086 5067>,
			<6693 5809 5376 5182 5101 5078>,
			<6687 5792 5343 5189 5110 5084>,
			<6688 5783 5328 5162 5094 5072>,
			<6690 5777 5318 5123 5068 5054>,
			<6693 5777 5315 5113 5059 5047>,
			<6700 5787 5314 5110 5057 5045>,
			<6709 5800 5315 5110 5056 5045>,
			<6722 5818 5320 5111 5056 5045>,
			<6737 5841 5331 5114 5057 5046>,
			<6751 5866 5342 5117 5059 5047>,
			<6763 5893 5356 5121 5061 5049>,
			<6775 5922 5370 5125 5064 5051>,
			<6788 5953 5387 5130 5067 5053>,
			<6802 5985 5406 5137 5071 5056>,
			<6816 6017 5425 5145 5074 5057>,
			<6831 6048 5447 5153 5077 5058>,
			<6847 6080 5469 5158 5078 5058>,
			<6865 6117 5490 5160 5077 5057>,
			<6885 6153 5513 5162 5074 5054>,
			<6909 6179 5538 5166 5074 5054>,
			<6935 6202 5566 5172 5077 5057>,
			<6969 6214 5593 5181 5081 5060>,
			<7018 6204 5617 5197 5086 5063>,
			<7086 6185 5635 5217 5092 5067>,
			<7176 6166 5650 5245 5100 5070>,
			<7294 6181 5640 5258 5115 5081>,
			<7318 6233 5574 5231 5115 5082>,
			<7380 6287 5576 5227 5110 5080>,
			<7510 6368 5590 5218 5104 5079>,
			<7689 6470 5614 5215 5103 5079>,
			<7957 6604 5651 5223 5104 5079>,
			<8496 6790 5692 5216 5100 5073>,
			<9940 7072 5728 5217 5095 5073>,
			<12748 7671 5832 5236 5106 5078>,
			<18165 9193 6071 5277 5118 5093>,
			<18165 9193 6071 5277 5118 5093>,
			<18165 9193 6071 5277 5118 5093>;
	};

};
